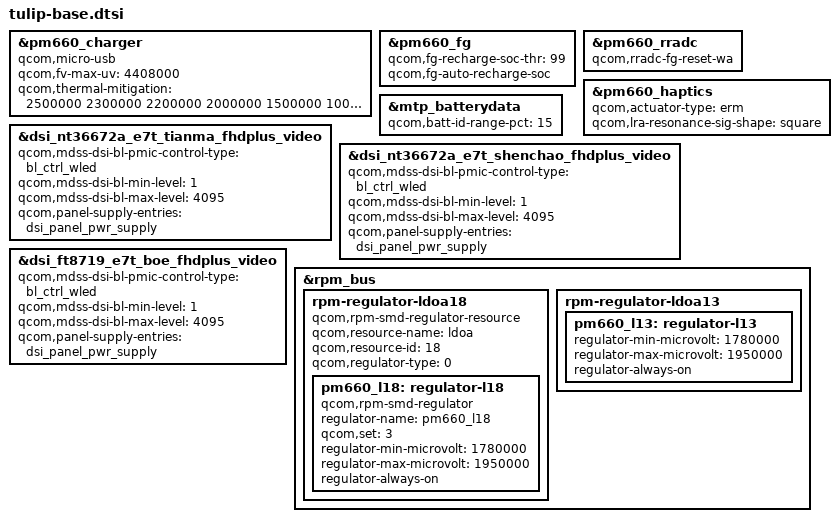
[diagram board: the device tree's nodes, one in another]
// SPDX-License-Identifier: GPL-2.0-only

#include "tulip-camera-sensor-mtp.dtsi"
#include "sdm636-i2c_e7t.dtsi"

/* msm-pm660.dtsi tulip specific diff */
&pm660_charger {
	qcom,micro-usb;
	qcom,fv-max-uv = <4408000>;
	qcom,thermal-mitigation = <2500000 2300000 2200000 2000000 1500000 1000000 800000 400000 100000>;
};

&pm660_fg {
	qcom,fg-recharge-soc-thr = <99>;
	qcom,fg-auto-recharge-soc;
};

&pm660_rradc {
	qcom,rradc-fg-reset-wa;
};

&pm660_haptics {
	qcom,actuator-type = "erm";
	qcom,lra-resonance-sig-shape = "square";
};

/* sdm660-mtp.dtsi tulip specific diff */
&mtp_batterydata {
	qcom,batt-id-range-pct = <15>;
	#include "fg-gen3-batterydata-l6660cos-4000mah.dtsi"
	#include "fg-gen3-batterydata-l6660desay-4000mah.dtsi"
	#include "fg-gen3-batterydata-l6660atl-4000mah.dtsi"
};

&dsi_nt36672a_e7t_tianma_fhdplus_video {
	qcom,mdss-dsi-bl-pmic-control-type = "bl_ctrl_wled";
	qcom,mdss-dsi-bl-min-level = <1>;
	qcom,mdss-dsi-bl-max-level = <4095>;
	qcom,panel-supply-entries = <&dsi_panel_pwr_supply>;
};

&dsi_nt36672a_e7t_shenchao_fhdplus_video {
	qcom,mdss-dsi-bl-pmic-control-type = "bl_ctrl_wled";
	qcom,mdss-dsi-bl-min-level = <1>;
	qcom,mdss-dsi-bl-max-level = <4095>;
	qcom,panel-supply-entries = <&dsi_panel_pwr_supply>;
};

&dsi_ft8719_e7t_boe_fhdplus_video {
	qcom,mdss-dsi-bl-pmic-control-type = "bl_ctrl_wled";
	qcom,mdss-dsi-bl-min-level = <1>;
	qcom,mdss-dsi-bl-max-level = <4095>;
	qcom,panel-supply-entries = <&dsi_panel_pwr_supply>;
};

/* SAR-sensor-regulator-e7t.dtsi */
&rpm_bus{
	rpm-regulator-ldoa18 {
		status = "ok";
		compatible = "qcom,rpm-smd-regulator-resource";
		qcom,resource-name = "ldoa";
		qcom,resource-id = <18>;
		qcom,regulator-type = <0>;

		pm660_l18:regulator-l18 {
			status = "ok";
			compatible = "qcom,rpm-smd-regulator";
			regulator-name = "pm660_l18";
			qcom,set = <3>;
			regulator-min-microvolt = <1780000>;
			regulator-max-microvolt = <1950000>;
			regulator-always-on;
		};
	};

	rpm-regulator-ldoa13 {
		status = "ok";
		pm660_l13: regulator-l13 {
			status = "ok";
			regulator-min-microvolt = <1780000>;
			regulator-max-microvolt = <1950000>;
			regulator-always-on;
		};
	};
}; 
